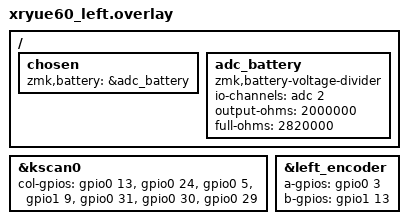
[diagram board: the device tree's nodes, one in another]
/*
 * Copyright (c) 2020 Pete Johanson
 *
 * SPDX-License-Identifier: MIT
 */

#include "xryue60.dtsi"

&kscan0 {
col-gpios
			= <&gpio0 13 GPIO_ACTIVE_HIGH>
			, <&gpio0 24 GPIO_ACTIVE_HIGH>
			, <&gpio0 5 GPIO_ACTIVE_HIGH>
			, <&gpio1 9 GPIO_ACTIVE_HIGH>			
			, <&gpio0 31 GPIO_ACTIVE_HIGH>
			, <&gpio0 30 GPIO_ACTIVE_HIGH>
			, <&gpio0 29 GPIO_ACTIVE_HIGH>
			;
};
&left_encoder {
        a-gpios = <&gpio0 3 (GPIO_ACTIVE_HIGH | GPIO_PULL_UP)>;
        b-gpios = <&gpio1 13 (GPIO_ACTIVE_HIGH | GPIO_PULL_UP)>;
        //steps = <48>;
        status = "okay";
    };

/ {
chosen {
zmk,battery = &adc_battery;
};
adc_battery: adc_battery {
    compatible = "zmk,battery-voltage-divider";
    io-channels = <&adc 2>;          // 因为使用了 P0.04 / AIN2
    output-ohms = <2000000>;         // 对应你的 R11 (2MΩ)
    full-ohms = <2820000>;           // 对应你的 R10 + R11 (820kΩ + 2MΩ)
};
};
